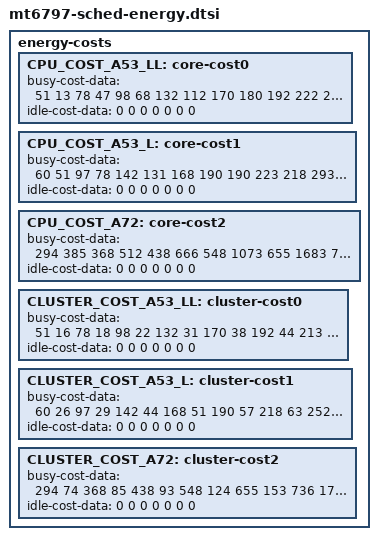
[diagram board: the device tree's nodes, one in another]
/*
 * MTK X20 (MT6797) specific energy cost model data. There are no unit
 * requirements for the data. Data can be normalized to any reference point,
 * but the normalization must be consistent. That is, one bogo-joule/watt must
 * be the same quantity for all data, but we don't care what it is.
 */

energy-costs {
	CPU_COST_A53_LL: core-cost0 {
		busy-cost-data = <
			51    13	/*  221MHz */
			78    47	/*  338MHz */
			98    68	/*  416MHz */
			132  112	/*  559MHz */
			170  180	/*  715MHz */
			192  222	/*  806MHz */
			213  277	/*  897MHz */
			226  317	/*  949MHZ */
			261  454	/* 1092MHz */
			267  502	/* 1118MHz */
		>;
		idle-cost-data = <
			  0		/* dpidle - deep idle */
			  0		/* SODI3 */
			  0		/* SODI */
		          0		/* MCDI */
			  0		/* slidle - slow idle */
		          0		/* rgidle - WFI */
		          0		/* active idle */
		>;
	};

	CPU_COST_A53_L: core-cost1 {
		busy-cost-data = <
			 60    51  	/*  325MHz */
			 97    78  	/*  468MHz */
			142   131	/*  650MHz */
			168   190	/*  741MHz */
			190   223	/*  832MHz */
			218   293	/*  949MHz */
			252   424	/* 1092MHz */
			276   481	/* 1209MHz */
			296   556	/* 1274MHz */
			324   769	/* 1417MHz */
		>;
		idle-cost-data = <
			  0		/* dpidle - deep idle */
			  0		/* SODI3 */
			  0		/* SODI */
		          0		/* MCDI */
			  0		/* slidle - slow idle */
		          0		/* rgidle - WFI */
		          0		/* active idle */
		>;
	};

	CPU_COST_A72: core-cost2 {
		busy-cost-data = <
			294  385	/*  676MHz */
			368  512	/*  845MHz */
			438  666	/* 1001MHz */
			548 1073	/* 1248MHz */
			655 1683	/* 1495MHz */
			736 2279	/* 1677MHz */
			777 2549	/* 1781MHz */
			879 3167	/* 1989MHz */
			936 3602	/* 2119MHz */
		       1024 4442	/* 2314MHz */
		>;
		idle-cost-data = <
			  0		/* dpidle - deep idle */
			  0		/* SODI3 */
			  0		/* SODI */
		          0		/* MCDI */
			  0		/* slidle - slow idle */
		          0		/* rgidle - WFI */
		          0		/* active idle */
		>;
	};

	CLUSTER_COST_A53_LL: cluster-cost0 {
		busy-cost-data = <
			 51   16	/*  221MHz */
			 78   18	/*  338MHz */
			 98   22	/*  416MHz */
			132   31	/*  559MHz */
			170   38	/*  715MHz */
			192   44	/*  806MHz */
			213   48	/*  897MHz */
			226   53	/*  949MHZ */
			261   58	/* 1092MHz */
			267   60	/* 1118MHz */
		>;
		idle-cost-data = <
			  0		/* dpidle - deep idle */
			  0		/* SODI3 */
			  0		/* SODI */
		          0		/* MCDI */
			  0		/* slidle - slow idle */
		          0		/* rgidle - WFI */
		          0		/* active idle */
		>;
	};
	CLUSTER_COST_A53_L: cluster-cost1 {
		busy-cost-data = <
			 60   26	/*  325MHz */
			 97   29	/*  468MHz */
			142   44	/*  650MHz */
			168   51	/*  741MHz */
			190   57	/*  832MHz */
			218   63	/*  949MHz */
			252   71	/* 1092MHz */
			276   79	/* 1209MHz */
			296   86	/* 1274MHz */
			324   94	/* 1417MHz */
		>;
		idle-cost-data = <
			  0		/* dpidle - deep idle */
			  0		/* SODI3 */
			  0		/* SODI */
		          0		/* MCDI */
			  0		/* slidle - slow idle */
		          0		/* rgidle - WFI */
		          0		/* active idle */
		>;
	};
	CLUSTER_COST_A72: cluster-cost2 {
		busy-cost-data = <
			294   74	/*  676MHz */
			368   85	/*  845MHz */
			438   93	/* 1001MHz */
			548  124	/* 1248MHz */
			655  153	/* 1495MHz */
			736  174	/* 1677MHz */
			777  192	/* 1781MHz */
			879  203	/* 1989MHz */
			936  216	/* 2119MHz */
		       1024  237	/* 2314MHz */
		>;
		idle-cost-data = <
			  0		/* dpidle - deep idle */
			  0		/* SODI3 */
			  0		/* SODI */
		          0		/* MCDI */
			  0		/* slidle - slow idle */
		          0		/* rgidle - WFI */
		          0		/* active idle */
		>;
	};
};
